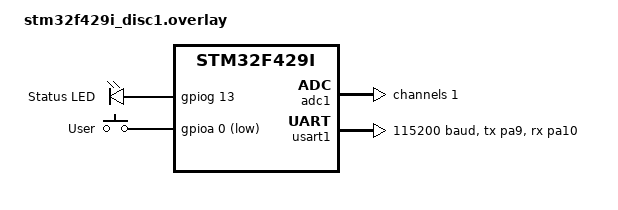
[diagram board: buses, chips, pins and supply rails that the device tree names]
#include <zephyr/dt-bindings/gpio/stm32-gpio.h>
#include <zephyr/dt-bindings/gpio/gpio.h>

/ {
	chosen {
		zephyr,console = &usart1;
		zephyr,shell-uart = &usart1;
	};

	aliases {
		led0 = &status_led;
		sw0 = &user_button;
	};

	app_leds {
		compatible = "gpio-leds";

		status_led: status-led {
			gpios = <&gpiog 13 GPIO_ACTIVE_HIGH>;
			label = "Status LED";
		};
	};

	gpio_keys {
		compatible = "gpio-keys";

		user_button: button {
			label = "User";
			gpios = <&gpioa 0 GPIO_ACTIVE_LOW>;
			zephyr,code = <INPUT_KEY_0>;
			status = "okay";
		};
	};
};

&adc1 {
	status = "okay";
	#address-cells = <1>;
	#size-cells = <0>;

	channel@1 {
		reg = <1>;
		zephyr,gain = "ADC_GAIN_1";
		zephyr,reference = "ADC_REF_INTERNAL";
		zephyr,acquisition-time = <ADC_ACQ_TIME_DEFAULT>;
		zephyr,resolution = <12>;
	};
};

&usart1 {
	pinctrl-0 = <&usart1_tx_pa9 &usart1_rx_pa10>;
	pinctrl-names = "default";
	current-speed = <115200>;
	status = "okay";
};
